VERSION ""

NS_ :

BS_:

BU_: BMS MC2

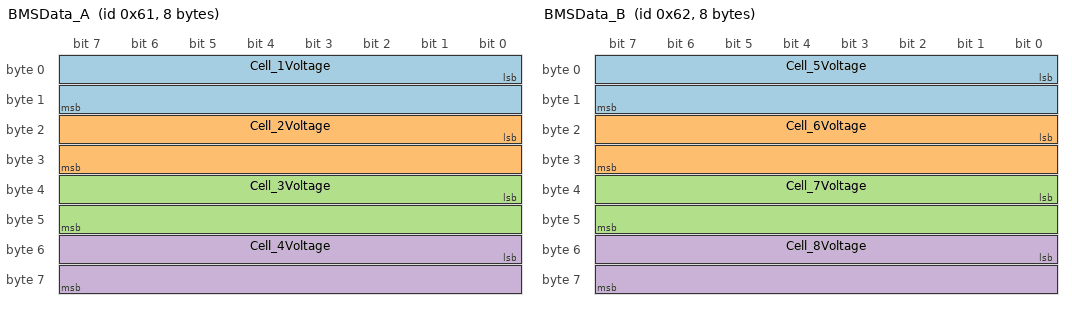
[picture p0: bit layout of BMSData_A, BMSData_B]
BO_ 97 BMSData_A: 8 BMS
 SG_ Cell_1Voltage : 0|16@1+ (0.00015258789,0) [0|5] "Volts"  MC2,BMS
 SG_ Cell_2Voltage : 16|16@1+ (0.00015258789,0) [0|5] "Volts"  MC2,BMS
 SG_ Cell_3Voltage : 32|16@1+ (0.00015258789,0) [0|5] "Volts"  MC2,BMS
 SG_ Cell_4Voltage : 48|16@1+ (0.00015258789,0) [0|5] "Volts"  MC2,BMS

BO_ 98 BMSData_B: 8 BMS
 SG_ Cell_5Voltage : 0|16@1+ (0.00015258789,0) [0|5] "Volts"  MC2,BMS
 SG_ Cell_6Voltage : 16|16@1+ (0.00015258789,0) [0|5] "Volts"  MC2,BMS
 SG_ Cell_7Voltage : 32|16@1+ (0.00015258789,0) [0|5] "Volts"  MC2,BMS
 SG_ Cell_8Voltage : 48|16@1+ (0.00015258789,0) [0|5] "Volts"  MC2,BMS

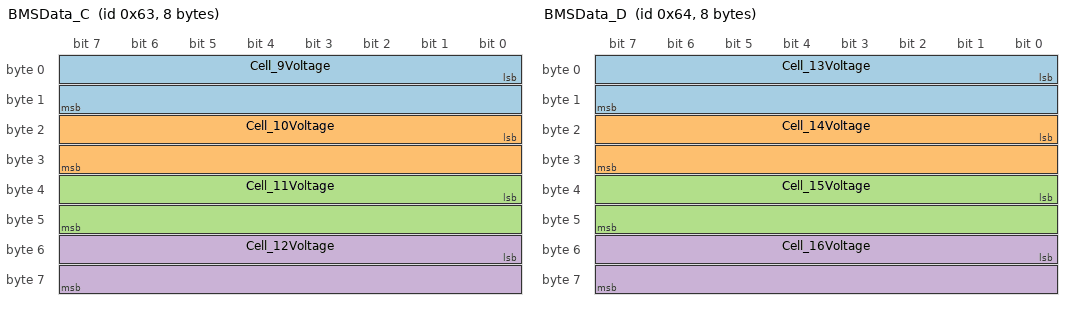
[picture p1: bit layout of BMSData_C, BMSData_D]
BO_ 99 BMSData_C: 8 BMS
 SG_ Cell_9Voltage : 0|16@1+ (0.00015258789,0) [0|5] "Volts"  MC2,BMS
 SG_ Cell_10Voltage : 16|16@1+ (0.00015258789,0) [0|5] "Volts"  MC2,BMS
 SG_ Cell_11Voltage : 32|16@1+ (0.00015258789,0) [0|5] "Volts"  MC2,BMS
 SG_ Cell_12Voltage : 48|16@1+ (0.00015258789,0) [0|5] "Volts"  MC2,BMS

BO_ 100 BMSData_D: 8 BMS
 SG_ Cell_13Voltage : 0|16@1+ (0.00015258789,0) [0|5] "Volts"  MC2,BMS
 SG_ Cell_14Voltage : 16|16@1+ (0.00015258789,0) [0|5] "Volts"  MC2,BMS
 SG_ Cell_15Voltage : 32|16@1+ (0.00015258789,0) [0|5] "Volts"  MC2,BMS
 SG_ Cell_16Voltage : 48|16@1+ (0.00015258789,0) [0|5] "Volts"  MC2,BMS

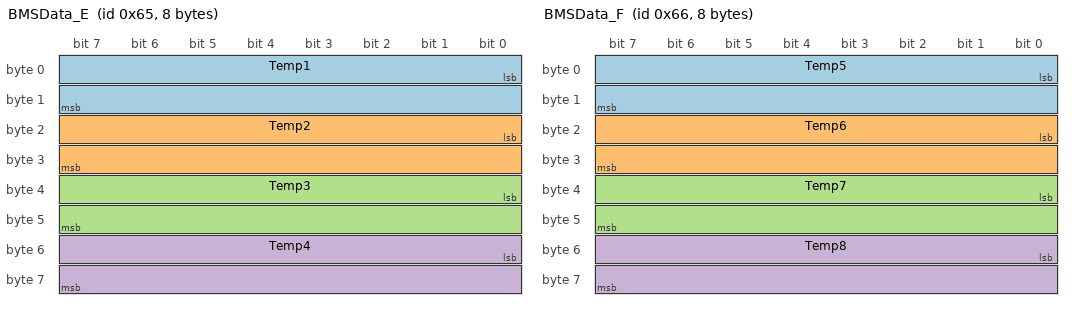
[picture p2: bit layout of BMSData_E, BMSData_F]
BO_ 101 BMSData_E: 8 BMS
 SG_ Temp1 : 0|16@1+ (0.00213626306,-40) [-40|100] "Deg C"  MC2
 SG_ Temp2 : 16|16@1+ (0.00213626306,-40) [-40|100] "Deg C"  MC2
 SG_ Temp3 : 32|16@1+ (0.00213626306,-40) [-40|100] "Deg C"  MC2
 SG_ Temp4 : 48|16@1+ (0.00213626306,-40) [-40|100] "Deg C"  MC2

BO_ 102 BMSData_F: 8 BMS
 SG_ Temp5 : 0|16@1+ (0.00213626306,-40) [-40|100] "Deg C"  MC2
 SG_ Temp6 : 16|16@1+ (0.00213626306,-40) [-40|100] "Deg C"  MC2
 SG_ Temp7 : 32|16@1+ (0.00213626306,-40) [-40|100] "Deg C"  MC2
 SG_ Temp8 : 48|16@1+ (0.00213626306,-40) [-40|100] "Deg C"  MC2

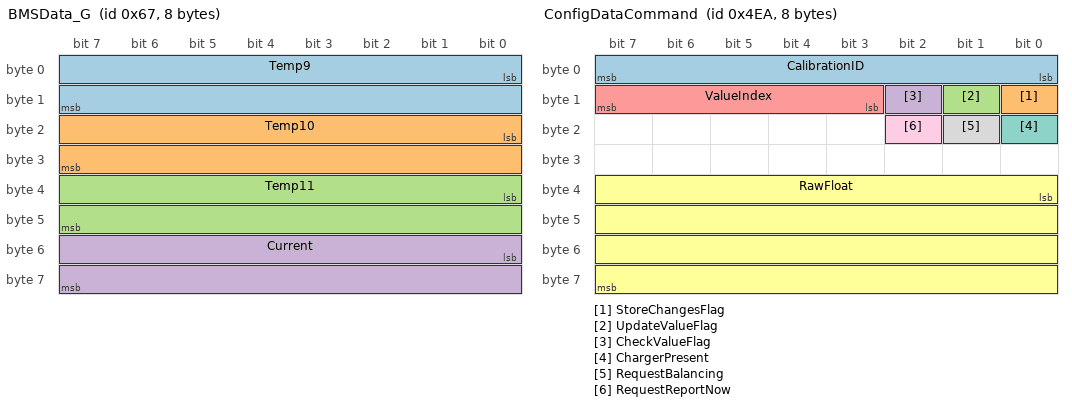
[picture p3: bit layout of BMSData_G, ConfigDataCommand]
BO_ 103 BMSData_G: 8 BMS
 SG_ Temp9 : 0|16@1+ (0.00213626306,-40) [-40|100] "Counts"  MC2
 SG_ Temp10 : 16|16@1+ (0.00213626306,-40) [-40|100] "Counts"  MC2
 SG_ Temp11 : 32|16@1+ (0.00213626306,-40) [-40|100] "Counts"  MC2
 SG_ Current : 48|16@1+ (1,0) [0|0] "Counts"  MC2

BO_ 1258 ConfigDataCommand: 8 MC2
 SG_ CalibrationID : 0|8@1+ (1,0) [0|0] ""  BMS
 SG_ StoreChangesFlag : 8|1@1+ (1,0) [0|0] ""  BMS
 SG_ UpdateValueFlag : 9|1@1+ (1,0) [0|0] ""  BMS
 SG_ CheckValueFlag : 10|1@1+ (1,0) [0|0] ""  BMS
 SG_ ValueIndex : 11|5@1+ (1,0) [0|0] ""  BMS
 SG_ RawFloat : 32|32@1+ (1,0) [0|0] ""  BMS
 SG_ ChargerPresent : 16|1@1+ (1,0) [0|0] ""  BMS
 SG_ RequestBalancing : 17|1@1+ (1,0) [0|0] ""  BMS
 SG_ RequestReportNow : 18|1@1+ (1,0) [0|0] ""  BMS

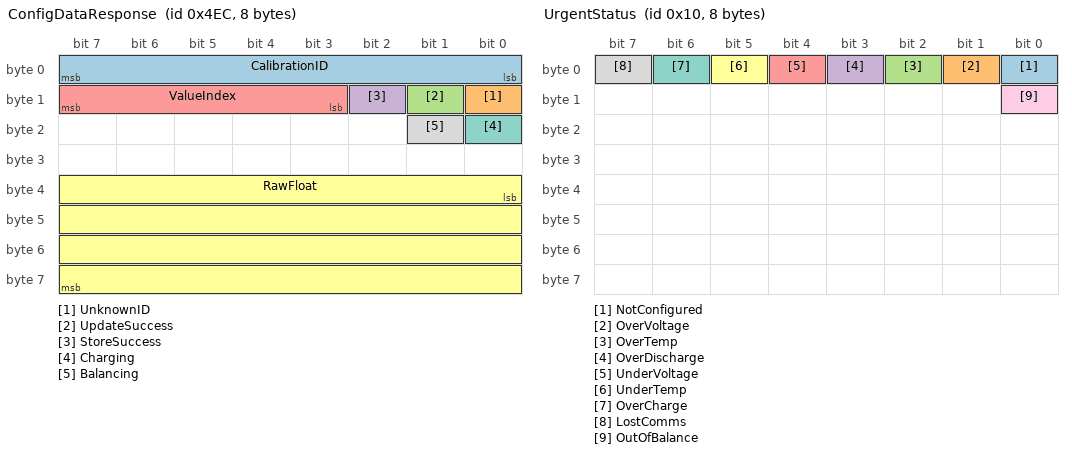
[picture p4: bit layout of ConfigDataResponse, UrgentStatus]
BO_ 1260 ConfigDataResponse: 8 BMS
 SG_ CalibrationID : 0|8@1+ (1,0) [0|0] ""  MC2
 SG_ UnknownID : 8|1@1+ (1,0) [0|0] ""  MC2
 SG_ UpdateSuccess : 9|1@1+ (1,0) [0|0] ""  MC2
 SG_ StoreSuccess : 10|1@1+ (1,0) [0|0] ""  MC2
 SG_ ValueIndex : 11|5@1+ (1,0) [0|0] ""  MC2
 SG_ RawFloat : 32|32@1+ (1,0) [0|0] ""  MC2
 SG_ Charging : 16|1@1+ (1,0) [0|0] ""  MC2
 SG_ Balancing : 17|1@1+ (1,0) [0|0] ""  MC2

BO_ 16 UrgentStatus: 8 BMS
 SG_ NotConfigured : 0|1@1+ (1,0) [0|0] ""  MC2
 SG_ OverVoltage : 1|1@1+ (1,0) [0|0] ""  MC2
 SG_ OverTemp : 2|1@1+ (1,0) [0|0] ""  MC2
 SG_ OverDischarge : 3|1@1+ (1,0) [0|0] ""  MC2
 SG_ UnderVoltage : 4|1@1+ (1,0) [0|0] ""  MC2
 SG_ UnderTemp : 5|1@1+ (1,0) [0|0] ""  MC2
 SG_ OverCharge : 6|1@1+ (1,0) [0|0] ""  MC2
 SG_ LostComms : 7|1@1+ (1,0) [0|0] ""  MC2
 SG_ OutOfBalance : 8|1@1+ (1,0) [0|0] ""  MC2

CM_ BU_ BMS "Main control unit for BMS operation";
CM_ BU_ MC2 "Main controller REV2 or equivalent";
